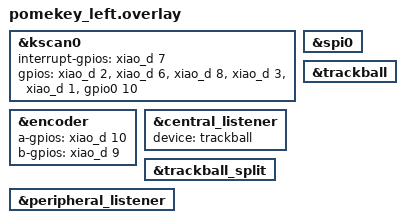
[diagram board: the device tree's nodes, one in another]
#include "pomekey.dtsi"

&kscan0 {
    interrupt-gpios = <&xiao_d 7 (GPIO_ACTIVE_HIGH | GPIO_PULL_DOWN)>; // gpio_interrupt: P1.12
    gpios
        = <&xiao_d 2 GPIO_ACTIVE_HIGH>   // gpio0: P0.28
        , <&xiao_d 6 GPIO_ACTIVE_HIGH>   // gpio1: P1.11
        , <&xiao_d 8 GPIO_ACTIVE_HIGH>   // gpio2: P1.13
        , <&xiao_d 3 GPIO_ACTIVE_HIGH>   // gpio3: P0.29
        , <&xiao_d 1 GPIO_ACTIVE_HIGH>   // gpio4: P0.03
        , <&gpio0 10 GPIO_ACTIVE_HIGH>   // gpio5: P0.10 (NFC2)
        ;
};

&encoder {
    status = "okay";
    a-gpios = <&xiao_d 10 (GPIO_ACTIVE_HIGH | GPIO_PULL_UP)>; // P1.15
    b-gpios = <&xiao_d 9 (GPIO_ACTIVE_HIGH | GPIO_PULL_UP)>;  // P1.14
};

&spi0 {
    status = "okay";
};

&trackball {
    status = "okay";
};

// 自身のセンサー(左側)をリスナーに登録
&central_listener {
    status = "okay";
    device = <&trackball>;
};

// ペリフェラル(右側)からの入力を受け取るリスナーを有効化
&trackball_split {
    status = "okay";
};

&peripheral_listener {
    status = "okay";
};
